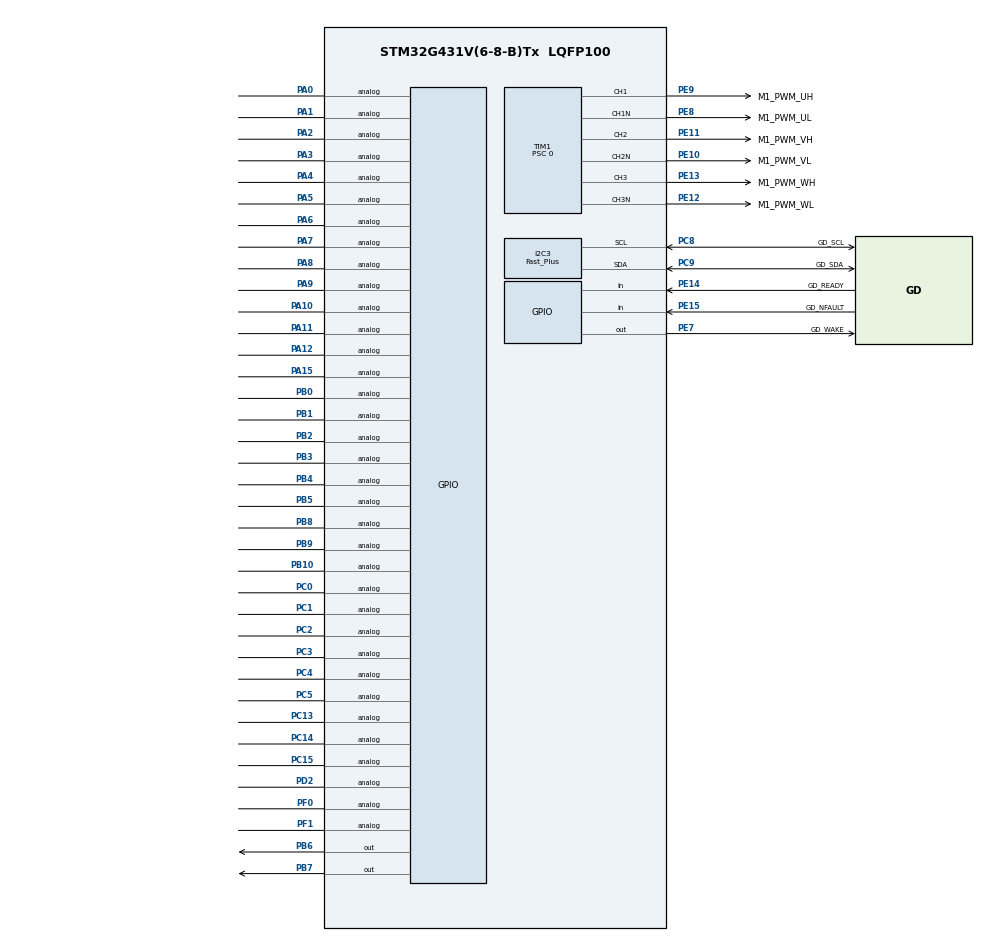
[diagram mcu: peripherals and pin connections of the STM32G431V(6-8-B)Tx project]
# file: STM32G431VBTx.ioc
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Dma.Request0=TIM1_CH4
Dma.TIM1_CH4.0.Direction=DMA_MEMORY_TO_PERIPH
Dma.TIM1_CH4.0.EventEnable=DISABLE
Dma.TIM1_CH4.0.Instance=DMA1_Channel1
Dma.TIM1_CH4.0.MemDataAlignment=DMA_MDATAALIGN_HALFWORD
Dma.TIM1_CH4.0.MemInc=DMA_MINC_ENABLE
Dma.TIM1_CH4.0.Mode=DMA_CIRCULAR
Dma.TIM1_CH4.0.PeriphDataAlignment=DMA_PDATAALIGN_HALFWORD
Dma.TIM1_CH4.0.PeriphInc=DMA_PINC_DISABLE
Dma.TIM1_CH4.0.Polarity=HAL_DMAMUX_REQ_GEN_RISING
Dma.TIM1_CH4.0.Priority=DMA_PRIORITY_HIGH
Dma.TIM1_CH4.0.RequestNumber=1
Dma.TIM1_CH4.0.SignalID=NONE
Dma.TIM1_CH4.0.SyncEnable=DISABLE
Dma.TIM1_CH4.0.SyncPolarity=HAL_DMAMUX_SYNC_NO_EVENT
Dma.TIM1_CH4.0.SyncRequestNumber=1
Dma.TIM1_CH4.0.SyncSignalID=NONE
I2C3.I2C_Speed_Mode=I2C_Fast_Plus
I2C3.Timing=0x4052060F
Mcu.Family=STM32G4
Mcu.Name=STM32G431V(6-8-B)Tx
Mcu.Package=LQFP100
NVIC.DMA1_Channel1_IRQn=true\:0\:0\:false\:false\:true\:false\:true\:true
NVIC.PriorityGroup=NVIC_PRIORITYGROUP_3
NVIC.TIM1_BRK_TIM15_IRQn=true\:6\:0\:true\:true\:true\:1\:true\:true\:true
NVIC.TIM1_CC_IRQn=true\:7\:0\:true\:false\:true\:true\:true\:true
NVIC.TIM1_TRG_COM_TIM17_IRQn=true\:0\:0\:false\:false\:true\:true\:true\:true
NVIC.TIM1_UP_TIM16_IRQn=true\:0\:0\:false\:true\:true\:2\:true\:true\:true
NVIC.TIM7_IRQn=true\:0\:0\:false\:false\:true\:true\:true\:true
PA0.Signal=GPIO_Analog
PA1.Signal=GPIO_Analog
PA10.Signal=GPIO_Analog
PA11.Signal=GPIO_Analog
PA12.Signal=GPIO_Analog
PA13.GPIO_Label=TMS
PA13.Mode=Serial_Wire
PA13.Signal=SYS_JTMS-SWDIO
PA14.GPIO_Label=TCK
PA14.Mode=Serial_Wire
PA14.Signal=SYS_JTCK-SWCLK
PA15.Signal=GPIO_Analog
PA2.Signal=GPIO_Analog
PA3.Signal=GPIO_Analog
PA4.Signal=GPIO_Analog
PA5.Signal=GPIO_Analog
PA6.Signal=GPIO_Analog
PA7.Signal=GPIO_Analog
PA8.Signal=GPIO_Analog
PA9.Signal=GPIO_Analog
PB0.Signal=GPIO_Analog
PB1.Signal=GPIO_Analog
PB10.Signal=GPIO_Analog
PB2.Signal=GPIO_Analog
PB3.Signal=GPIO_Analog
PB4.Signal=GPIO_Analog
PB5.Signal=GPIO_Analog
PB6.Signal=GPIO_Output
PB7.Signal=GPIO_Output
PB8-BOOT0.Signal=GPIO_Analog
PB9.Signal=GPIO_Analog
PC0.Signal=GPIO_Analog
PC1.Signal=GPIO_Analog
PC13.Signal=GPIO_Analog
PC14-OSC32_IN.Signal=GPIO_Analog
PC15-OSC32_OUT.Signal=GPIO_Analog
PC2.Signal=GPIO_Analog
PC3.Signal=GPIO_Analog
PC4.Signal=GPIO_Analog
PC5.Signal=GPIO_Analog
PC8.GPIO_Label=GD_SCL
PC8.GPIO_Pu=GPIO_PULLUP
PC8.Mode=I2C
PC8.Signal=I2C3_SCL
PC9.GPIO_Label=GD_SDA
PC9.GPIO_Pu=GPIO_PULLUP
PC9.Mode=I2C
PC9.Signal=I2C3_SDA
PD2.Signal=GPIO_Analog
PE10.GPIO_Label=M1_PWM_VL
PE10.GPIO_PuPd=GPIO_PULLDOWN
PE10.GPIO_Speed=GPIO_SPEED_FREQ_HIGH
PE10.Mode=PWM Generation2 CH2 CH2N
PE10.Signal=TIM1_CH2N
PE11.GPIO_Label=M1_PWM_VH
PE11.GPIO_PuPd=GPIO_PULLDOWN
PE11.GPIO_Speed=GPIO_SPEED_FREQ_HIGH
PE11.Signal=S_TIM1_CH2
PE12.GPIO_Label=M1_PWM_WL
PE12.GPIO_PuPd=GPIO_PULLDOWN
PE12.GPIO_Speed=GPIO_SPEED_FREQ_HIGH
PE12.Mode=PWM Generation3 CH3 CH3N
PE12.Signal=TIM1_CH3N
PE13.GPIO_Label=M1_PWM_WH
PE13.GPIO_PuPd=GPIO_PULLDOWN
PE13.GPIO_Speed=GPIO_SPEED_FREQ_HIGH
PE13.Signal=S_TIM1_CH3
PE14.GPIO_Label=GD_READY
PE14.GPIO_PuPd=GPIO_PULLUP
PE14.Signal=GPIO_Input
PE15.GPIO_Label=GD_NFAULT
PE15.GPIO_PuPd=GPIO_PULLUP
PE15.Signal=GPIO_Input
PE7.GPIO_Label=GD_WAKE
PE7.Signal=GPIO_Output
PE8.GPIO_Label=M1_PWM_UL
PE8.GPIO_PuPd=GPIO_PULLDOWN
PE8.GPIO_Speed=GPIO_SPEED_FREQ_HIGH
PE8.Mode=PWM Generation1 CH1 CH1N
PE8.Signal=TIM1_CH1N
PE9.GPIO_Label=M1_PWM_UH
PE9.GPIO_PuPd=GPIO_PULLDOWN
PE9.GPIO_Speed=GPIO_SPEED_FREQ_HIGH
PE9.Signal=S_TIM1_CH1
PF0-OSC_IN.Signal=GPIO_Analog
PF1-OSC_OUT.Signal=GPIO_Analog
ProjectManager.HeapSize=0x200
ProjectManager.StackSize=0x400
ProjectManager.TargetToolchain=STM32CubeIDE
RCC.ADC12CLockSelection=RCC_ADC12CLKSOURCE_PLL
RCC.ADC12Freq_Value=170000000
RCC.ADC345CLockSelection=RCC_ADC345CLKSOURCE_PLL
RCC.ADC345Freq_Value=42500000
RCC.AHBFreq_Value=170000000
RCC.APB1Freq_Value=170000000
RCC.APB1TimFreq_Value=170000000
RCC.APB2Freq_Value=170000000
RCC.APB2TimFreq_Value=170000000
RCC.CortexFreq_Value=170000000
RCC.EXTERNAL_CLOCK_VALUE=12288000
RCC.HCLKFreq_Value=170000000
RCC.HSE_VALUE=24000000
RCC.HSI48_VALUE=48000000
RCC.HSI_VALUE=16000000
RCC.LSE_VALUE=32768
RCC.PLLM=RCC_PLLM_DIV4
RCC.PLLN=85
RCC.SYSCLKFreq_VALUE=170000000
RCC.SYSCLKSource=RCC_SYSCLKSOURCE_PLLCLK
RCC.USBFreq_Value=170000000
RCC.VCOOutputFreq_Value=340000000
SH.S_TIM1_CH1.0=TIM1_CH1,PWM Generation1 CH1 CH1N
SH.S_TIM1_CH2.0=TIM1_CH2,PWM Generation2 CH2 CH2N
SH.S_TIM1_CH3.0=TIM1_CH3,PWM Generation3 CH3 CH3N
TIM1.AutoReloadPreload=TIM_AUTORELOAD_PRELOAD_DISABLE
TIM1.AutomaticOutput=TIM_AUTOMATICOUTPUT_DISABLE
TIM1.Break2Filter=3
TIM1.Break2Polarity=TIM_BREAK2POLARITY_HIGH
TIM1.Break2State=TIM_BREAK2_DISABLE
TIM1.BreakFilter=3
TIM1.BreakPolarity=TIM_BREAKPOLARITY_HIGH
TIM1.BreakState=TIM_BREAK_ENABLE
TIM1.Channel-Output\ Compare4\ No\ Output=TIM_CHANNEL_4
TIM1.Channel-PWM\ Generation1\ CH1\ CH1N=TIM_CHANNEL_1
TIM1.Channel-PWM\ Generation2\ CH2\ CH2N=TIM_CHANNEL_2
TIM1.Channel-PWM\ Generation3\ CH3\ CH3N=TIM_CHANNEL_3
TIM1.ClearInputSource=TIM_CLEARINPUTSOURCE_NONE
TIM1.ClockDivision=TIM_CLOCKDIVISION_DIV1
TIM1.CounterMode=TIM_COUNTERMODE_CENTERALIGNED2
TIM1.LockLevel=TIM_LOCKLEVEL_OFF
TIM1.OCIdleState_4=TIM_OCIDLESTATE_RESET
TIM1.OCMode_4=TIM_OCMODE_TOGGLE
TIM1.OCPolarity_4=TIM_OCPOLARITY_HIGH
TIM1.OffStateIDLEMode=TIM_OSSI_ENABLE
TIM1.PeriodNoDither=((PWM_PERIOD_CYCLES) / 2)
TIM1.Prescaler=0
TIM1.RepetitionCounter=0
TIM1.SourceBRK2COMP1=TIM_BREAKINPUTSOURCE_DISABLE
TIM1.SourceBRK2COMP2=TIM_BREAKINPUTSOURCE_DISABLE
TIM1.SourceBRK2COMP4=TIM_BREAKINPUTSOURCE_DISABLE
TIM1.SourceBRK2DigInput=TIM_BREAKINPUTSOURCE_DISABLE
TIM1.SourceBRKCOMP3=TIM_BREAKINPUTSOURCE_DISABLE
TIM1.TIM_MasterOutputTrigger=TIM_TRGO_OC4REF
TIM1.TIM_MasterOutputTrigger2=TIM_TRGO2_RESET
TIM1.TIM_MasterSlaveMode=TIM_MASTERSLAVEMODE_DISABLE
TIM7.PeriodNoDither=42499
VP_CORDIC_VS_CORDIC.Mode=CORDIC_Activate
VP_SYS_VS_DBSignals.Mode=DisableDeadBatterySignals
VP_TIM1_VS_no_output4.Mode=Output Compare4 No Output
VP_TIM7_VS_ClockSourceINT.Mode=Enable_Timer
board=custom

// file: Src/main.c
/* USER CODE BEGIN Header */
/**
  ******************************************************************************
  * @file           : main.c
  * @brief          : Main program body
  ******************************************************************************
  * @attention
  *
  * Copyright (c) 2025 STMicroelectronics.
  * All rights reserved.
  *
  * This software is licensed under terms that can be found in the LICENSE file
  * in the root directory of this software component.
  * If no LICENSE file comes with this software, it is provided AS-IS.
  *
  ******************************************************************************
  */
/* USER CODE END Header */
#include "main.h"

/* USER CODE BEGIN Includes */
#include "SocketBoardTest.h"

/* USER CODE END Includes */

void SystemClock_Config(void);
static void MX_GPIO_Init(void);
static void MX_DMA_Init(void);
static void MX_CORDIC_Init(void);
static void MX_TIM1_Init(void);
static void MX_I2C3_Init(void);
static void MX_TIM7_Init(void);
static void MX_NVIC_Init(void);

/* USER CODE BEGIN 0 */
uint8_t testProcess = 0;
uint8_t cGPIOTestResults[GPIO_TEST_PIN_CNT]; // 테스트 결과 저장 배열 (0: 실패, 1: 성공)

/* USER CODE END 0 */

int main(void)
{

  /* MCU Configuration--------------------------------------------------------*/

  /* Reset of all peripherals, Initializes the Flash interface and the Systick. */
  LL_APB2_GRP1_EnableClock(LL_APB2_GRP1_PERIPH_SYSCFG);
  LL_APB1_GRP1_EnableClock(LL_APB1_GRP1_PERIPH_PWR);

  /* System interrupt init*/
  NVIC_SetPriorityGrouping(NVIC_PRIORITYGROUP_3);

  /** Disable the internal Pull-Up in Dead Battery pins of UCPD peripheral
  */
  LL_PWR_DisableUCPDDeadBattery();

  /* Configure the system clock */
  SystemClock_Config();

  /* Initialize all configured peripherals */
  MX_GPIO_Init();
  MX_DMA_Init();
  MX_CORDIC_Init();
  MX_TIM1_Init();
  MX_I2C3_Init();
  MX_TIM7_Init();

  /* Initialize interrupts */
  MX_NVIC_Init();

  /* Infinite loop */
  /* USER CODE BEGIN WHILE */

  while (1)
  {
	  if(testProcess == 1)
	  {
		  memset(cGPIOTestResults, 0, sizeof(cGPIOTestResults));
		  GPIO_TestProcess(cGPIOTestResults);
		  testProcess = 0;
	  }

    /* USER CODE END WHILE */

  }
}

void SystemClock_Config(void)
{
  LL_FLASH_SetLatency(LL_FLASH_LATENCY_4);
  while(LL_FLASH_GetLatency() != LL_FLASH_LATENCY_4)
  {
  }
  LL_PWR_EnableRange1BoostMode();
  LL_RCC_HSI_Enable();
   /* Wait till HSI is ready */
  while(LL_RCC_HSI_IsReady() != 1)
  {
  }

  LL_RCC_HSI_SetCalibTrimming(64);
  LL_RCC_PLL_ConfigDomain_SYS(LL_RCC_PLLSOURCE_HSI, LL_RCC_PLLM_DIV_4, 85, LL_RCC_PLLR_DIV_2);
  LL_RCC_PLL_EnableDomain_SYS();
  LL_RCC_PLL_Enable();
   /* Wait till PLL is ready */
  while(LL_RCC_PLL_IsReady() != 1)
  {
  }

  LL_RCC_SetSysClkSource(LL_RCC_SYS_CLKSOURCE_PLL);
  LL_RCC_SetAHBPrescaler(LL_RCC_SYSCLK_DIV_2);
   /* Wait till System clock is ready */
  while(LL_RCC_GetSysClkSource() != LL_RCC_SYS_CLKSOURCE_STATUS_PLL)
  {
  }

  /* Insure 1us transition state at intermediate medium speed clock*/
  for (__IO uint32_t i = (170 >> 1); i !=0; i--);

  /* Set AHB prescaler*/
  LL_RCC_SetAHBPrescaler(LL_RCC_SYSCLK_DIV_1);
  LL_RCC_SetAPB1Prescaler(LL_RCC_APB1_DIV_1);
  LL_RCC_SetAPB2Prescaler(LL_RCC_APB2_DIV_1);

  LL_Init1msTick(170000000);

  LL_SetSystemCoreClock(170000000);
}

/**
  * @brief NVIC Configuration.
  * @retval None
  */
static void MX_NVIC_Init(void)
{
  /* TIM1_BRK_TIM15_IRQn interrupt configuration */
  NVIC_SetPriority(TIM1_BRK_TIM15_IRQn, NVIC_EncodePriority(NVIC_GetPriorityGrouping(),6, 0));
  NVIC_EnableIRQ(TIM1_BRK_TIM15_IRQn);
  /* TIM1_UP_TIM16_IRQn interrupt configuration */
  NVIC_SetPriority(TIM1_UP_TIM16_IRQn, NVIC_EncodePriority(NVIC_GetPriorityGrouping(),0, 0));
  NVIC_EnableIRQ(TIM1_UP_TIM16_IRQn);
}

static void MX_CORDIC_Init(void)
{

  /* Peripheral clock enable */
  LL_AHB1_GRP1_EnableClock(LL_AHB1_GRP1_PERIPH_CORDIC);

  /* nothing else to be configured */

}

static void MX_I2C3_Init(void)
{

  LL_I2C_InitTypeDef I2C_InitStruct = {0};

  LL_GPIO_InitTypeDef GPIO_InitStruct = {0};

  LL_RCC_SetI2CClockSource(LL_RCC_I2C3_CLKSOURCE_PCLK1);

  LL_AHB2_GRP1_EnableClock(LL_AHB2_GRP1_PERIPH_GPIOC);
  /**I2C3 GPIO Configuration
  PC8   ------> I2C3_SCL
  PC9   ------> I2C3_SDA
  */
  GPIO_InitStruct.Pin = GD_SCL_Pin;
  GPIO_InitStruct.Mode = LL_GPIO_MODE_ALTERNATE;
  GPIO_InitStruct.Speed = LL_GPIO_SPEED_FREQ_LOW;
  GPIO_InitStruct.OutputType = LL_GPIO_OUTPUT_OPENDRAIN;
  GPIO_InitStruct.Pull = LL_GPIO_PULL_UP;
  GPIO_InitStruct.Alternate = LL_GPIO_AF_8;
  LL_GPIO_Init(GD_SCL_GPIO_Port, &GPIO_InitStruct);

  GPIO_InitStruct.Pin = GD_SDA_Pin;
  GPIO_InitStruct.Mode = LL_GPIO_MODE_ALTERNATE;
  GPIO_InitStruct.Speed = LL_GPIO_SPEED_FREQ_LOW;
  GPIO_InitStruct.OutputType = LL_GPIO_OUTPUT_OPENDRAIN;
  GPIO_InitStruct.Pull = LL_GPIO_PULL_UP;
  GPIO_InitStruct.Alternate = LL_GPIO_AF_8;
  LL_GPIO_Init(GD_SDA_GPIO_Port, &GPIO_InitStruct);

  /* Peripheral clock enable */
  LL_APB1_GRP1_EnableClock(LL_APB1_GRP1_PERIPH_I2C3);

  /** I2C Initialization
  */
  I2C_InitStruct.PeripheralMode = LL_I2C_MODE_I2C;
  I2C_InitStruct.Timing = 0x4052060F;
  I2C_InitStruct.AnalogFilter = LL_I2C_ANALOGFILTER_ENABLE;
  I2C_InitStruct.DigitalFilter = 0;
  I2C_InitStruct.OwnAddress1 = 0;
  I2C_InitStruct.TypeAcknowledge = LL_I2C_ACK;
  I2C_InitStruct.OwnAddrSize = LL_I2C_OWNADDRESS1_7BIT;
  LL_I2C_Init(I2C3, &I2C_InitStruct);
  LL_I2C_EnableAutoEndMode(I2C3);
  LL_I2C_SetOwnAddress2(I2C3, 0, LL_I2C_OWNADDRESS2_NOMASK);
  LL_I2C_DisableOwnAddress2(I2C3);
  LL_I2C_DisableGeneralCall(I2C3);
  LL_I2C_EnableClockStretching(I2C3);

  /** I2C Fast mode Plus enable
  */
  LL_SYSCFG_EnableFastModePlus(LL_SYSCFG_I2C_FASTMODEPLUS_I2C3);

}

static void MX_TIM1_Init(void)
{

  LL_TIM_InitTypeDef TIM_InitStruct = {0};
  LL_TIM_OC_InitTypeDef TIM_OC_InitStruct = {0};
  LL_TIM_BDTR_InitTypeDef TIM_BDTRInitStruct = {0};

  LL_GPIO_InitTypeDef GPIO_InitStruct = {0};

  /* Peripheral clock enable */
  LL_APB2_GRP1_EnableClock(LL_APB2_GRP1_PERIPH_TIM1);

  /* TIM1 DMA Init */

  /* TIM1_CH4 Init */
  LL_DMA_SetPeriphRequest(DMA1, LL_DMA_CHANNEL_1, LL_DMAMUX_REQ_TIM1_CH4);

  LL_DMA_SetDataTransferDirection(DMA1, LL_DMA_CHANNEL_1, LL_DMA_DIRECTION_MEMORY_TO_PERIPH);

  LL_DMA_SetChannelPriorityLevel(DMA1, LL_DMA_CHANNEL_1, LL_DMA_PRIORITY_HIGH);

  LL_DMA_SetMode(DMA1, LL_DMA_CHANNEL_1, LL_DMA_MODE_CIRCULAR);

  LL_DMA_SetPeriphIncMode(DMA1, LL_DMA_CHANNEL_1, LL_DMA_PERIPH_NOINCREMENT);

  LL_DMA_SetMemoryIncMode(DMA1, LL_DMA_CHANNEL_1, LL_DMA_MEMORY_INCREMENT);

  LL_DMA_SetPeriphSize(DMA1, LL_DMA_CHANNEL_1, LL_DMA_PDATAALIGN_HALFWORD);

  LL_DMA_SetMemorySize(DMA1, LL_DMA_CHANNEL_1, LL_DMA_MDATAALIGN_HALFWORD);

  /* TIM1 interrupt Init */
  NVIC_SetPriority(TIM1_TRG_COM_TIM17_IRQn, NVIC_EncodePriority(NVIC_GetPriorityGrouping(),0, 0));
  NVIC_EnableIRQ(TIM1_TRG_COM_TIM17_IRQn);
  NVIC_SetPriority(TIM1_CC_IRQn, NVIC_EncodePriority(NVIC_GetPriorityGrouping(),7, 0));
  NVIC_EnableIRQ(TIM1_CC_IRQn);

  TIM_InitStruct.Prescaler = 0;
  TIM_InitStruct.CounterMode = LL_TIM_COUNTERMODE_CENTER_UP;
  TIM_InitStruct.Autoreload = ((PWM_PERIOD_CYCLES) / 2);
  TIM_InitStruct.ClockDivision = LL_TIM_CLOCKDIVISION_DIV1;
  TIM_InitStruct.RepetitionCounter = 0;
  LL_TIM_Init(TIM1, &TIM_InitStruct);
  LL_TIM_DisableARRPreload(TIM1);
  LL_TIM_OC_EnablePreload(TIM1, LL_TIM_CHANNEL_CH1);
  TIM_OC_InitStruct.OCMode = LL_TIM_OCMODE_PWM1;
  TIM_OC_InitStruct.OCState = LL_TIM_OCSTATE_DISABLE;
  TIM_OC_InitStruct.OCNState = LL_TIM_OCSTATE_DISABLE;
  TIM_OC_InitStruct.CompareValue = 0;
  TIM_OC_InitStruct.OCPolarity = LL_TIM_OCPOLARITY_HIGH;
  TIM_OC_InitStruct.OCNPolarity = LL_TIM_OCPOLARITY_HIGH;
  TIM_OC_InitStruct.OCIdleState = LL_TIM_OCIDLESTATE_LOW;
  TIM_OC_InitStruct.OCNIdleState = LL_TIM_OCIDLESTATE_LOW;
  LL_TIM_OC_Init(TIM1, LL_TIM_CHANNEL_CH1, &TIM_OC_InitStruct);
  LL_TIM_OC_DisableFast(TIM1, LL_TIM_CHANNEL_CH1);
  LL_TIM_OC_EnablePreload(TIM1, LL_TIM_CHANNEL_CH2);
  LL_TIM_OC_Init(TIM1, LL_TIM_CHANNEL_CH2, &TIM_OC_InitStruct);
  LL_TIM_OC_DisableFast(TIM1, LL_TIM_CHANNEL_CH2);
  LL_TIM_OC_EnablePreload(TIM1, LL_TIM_CHANNEL_CH3);
  LL_TIM_OC_Init(TIM1, LL_TIM_CHANNEL_CH3, &TIM_OC_InitStruct);
  LL_TIM_OC_DisableFast(TIM1, LL_TIM_CHANNEL_CH3);
  TIM_OC_InitStruct.OCMode = LL_TIM_OCMODE_TOGGLE;
  LL_TIM_OC_Init(TIM1, LL_TIM_CHANNEL_CH4, &TIM_OC_InitStruct);
  LL_TIM_OC_DisableFast(TIM1, LL_TIM_CHANNEL_CH4);
  LL_TIM_SetTriggerOutput(TIM1, LL_TIM_TRGO_OC4REF);
  LL_TIM_SetTriggerOutput2(TIM1, LL_TIM_TRGO2_RESET);
  LL_TIM_DisableMasterSlaveMode(TIM1);
  TIM_BDTRInitStruct.OSSRState = LL_TIM_OSSR_DISABLE;
  TIM_BDTRInitStruct.OSSIState = LL_TIM_OSSI_ENABLE;
  TIM_BDTRInitStruct.LockLevel = LL_TIM_LOCKLEVEL_OFF;
  TIM_BDTRInitStruct.DeadTime = 0;
  TIM_BDTRInitStruct.BreakState = LL_TIM_BREAK_ENABLE;
  TIM_BDTRInitStruct.BreakPolarity = LL_TIM_BREAK_POLARITY_HIGH;
  TIM_BDTRInitStruct.BreakFilter = LL_TIM_BREAK_FILTER_FDIV1_N8;
  TIM_BDTRInitStruct.BreakAFMode = LL_TIM_BREAK_AFMODE_INPUT;
  TIM_BDTRInitStruct.Break2State = LL_TIM_BREAK2_DISABLE;
  TIM_BDTRInitStruct.Break2Polarity = LL_TIM_BREAK2_POLARITY_HIGH;
  TIM_BDTRInitStruct.Break2Filter = LL_TIM_BREAK2_FILTER_FDIV1_N8;
  TIM_BDTRInitStruct.Break2AFMode = LL_TIM_BREAK_AFMODE_INPUT;
  TIM_BDTRInitStruct.AutomaticOutput = LL_TIM_AUTOMATICOUTPUT_DISABLE;
  LL_TIM_BDTR_Init(TIM1, &TIM_BDTRInitStruct);
  LL_AHB2_GRP1_EnableClock(LL_AHB2_GRP1_PERIPH_GPIOE);
  /**TIM1 GPIO Configuration
  PE8   ------> TIM1_CH1N
  PE9   ------> TIM1_CH1
  PE10   ------> TIM1_CH2N
  PE11   ------> TIM1_CH2
  PE12   ------> TIM1_CH3N
  PE13   ------> TIM1_CH3
  */
  GPIO_InitStruct.Pin = M1_PWM_UL_Pin;
  GPIO_InitStruct.Mode = LL_GPIO_MODE_ALTERNATE;
  GPIO_InitStruct.Speed = LL_GPIO_SPEED_FREQ_HIGH;
  GPIO_InitStruct.OutputType = LL_GPIO_OUTPUT_PUSHPULL;
  GPIO_InitStruct.Pull = LL_GPIO_PULL_DOWN;
  GPIO_InitStruct.Alternate = LL_GPIO_AF_2;
  LL_GPIO_Init(M1_PWM_UL_GPIO_Port, &GPIO_InitStruct);

  GPIO_InitStruct.Pin = M1_PWM_UH_Pin;
  GPIO_InitStruct.Mode = LL_GPIO_MODE_ALTERNATE;
  GPIO_InitStruct.Speed = LL_GPIO_SPEED_FREQ_HIGH;
  GPIO_InitStruct.OutputType = LL_GPIO_OUTPUT_PUSHPULL;
  GPIO_InitStruct.Pull = LL_GPIO_PULL_DOWN;
  GPIO_InitStruct.Alternate = LL_GPIO_AF_2;
  LL_GPIO_Init(M1_PWM_UH_GPIO_Port, &GPIO_InitStruct);

  GPIO_InitStruct.Pin = M1_PWM_VL_Pin;
  GPIO_InitStruct.Mode = LL_GPIO_MODE_ALTERNATE;
  GPIO_InitStruct.Speed = LL_GPIO_SPEED_FREQ_HIGH;
  GPIO_InitStruct.OutputType = LL_GPIO_OUTPUT_PUSHPULL;
  GPIO_InitStruct.Pull = LL_GPIO_PULL_DOWN;
  GPIO_InitStruct.Alternate = LL_GPIO_AF_2;
  LL_GPIO_Init(M1_PWM_VL_GPIO_Port, &GPIO_InitStruct);

  GPIO_InitStruct.Pin = M1_PWM_VH_Pin;
  GPIO_InitStruct.Mode = LL_GPIO_MODE_ALTERNATE;
  GPIO_InitStruct.Speed = LL_GPIO_SPEED_FREQ_HIGH;
  GPIO_InitStruct.OutputType = LL_GPIO_OUTPUT_PUSHPULL;
  GPIO_InitStruct.Pull = LL_GPIO_PULL_DOWN;
  GPIO_InitStruct.Alternate = LL_GPIO_AF_2;
  LL_GPIO_Init(M1_PWM_VH_GPIO_Port, &GPIO_InitStruct);

  GPIO_InitStruct.Pin = M1_PWM_WL_Pin;
  GPIO_InitStruct.Mode = LL_GPIO_MODE_ALTERNATE;
  GPIO_InitStruct.Speed = LL_GPIO_SPEED_FREQ_HIGH;
  GPIO_InitStruct.OutputType = LL_GPIO_OUTPUT_PUSHPULL;
  GPIO_InitStruct.Pull = LL_GPIO_PULL_DOWN;
  GPIO_InitStruct.Alternate = LL_GPIO_AF_2;
  LL_GPIO_Init(M1_PWM_WL_GPIO_Port, &GPIO_InitStruct);

  GPIO_InitStruct.Pin = M1_PWM_WH_Pin;
  GPIO_InitStruct.Mode = LL_GPIO_MODE_ALTERNATE;
  GPIO_InitStruct.Speed = LL_GPIO_SPEED_FREQ_HIGH;
  GPIO_InitStruct.OutputType = LL_GPIO_OUTPUT_PUSHPULL;
  GPIO_InitStruct.Pull = LL_GPIO_PULL_DOWN;
  GPIO_InitStruct.Alternate = LL_GPIO_AF_2;
  LL_GPIO_Init(M1_PWM_WH_GPIO_Port, &GPIO_InitStruct);

}

static void MX_TIM7_Init(void)
{

  LL_TIM_InitTypeDef TIM_InitStruct = {0};

  /* Peripheral clock enable */
  LL_APB1_GRP1_EnableClock(LL_APB1_GRP1_PERIPH_TIM7);

  /* TIM7 interrupt Init */
  NVIC_SetPriority(TIM7_IRQn, NVIC_EncodePriority(NVIC_GetPriorityGrouping(),0, 0));
  NVIC_EnableIRQ(TIM7_IRQn);

  TIM_InitStruct.Prescaler = 0;
  TIM_InitStruct.CounterMode = LL_TIM_COUNTERMODE_UP;
  TIM_InitStruct.Autoreload = 42499;
  LL_TIM_Init(TIM7, &TIM_InitStruct);
  LL_TIM_DisableARRPreload(TIM7);
  LL_TIM_SetTriggerOutput(TIM7, LL_TIM_TRGO_RESET);
  LL_TIM_DisableMasterSlaveMode(TIM7);

}

static void MX_DMA_Init(void)
{

  /* Init with LL driver */
  /* DMA controller clock enable */
  LL_AHB1_GRP1_EnableClock(LL_AHB1_GRP1_PERIPH_DMAMUX1);
  LL_AHB1_GRP1_EnableClock(LL_AHB1_GRP1_PERIPH_DMA1);

  /* DMA interrupt init */
  /* DMA1_Channel1_IRQn interrupt configuration */
  NVIC_SetPriority(DMA1_Channel1_IRQn, NVIC_EncodePriority(NVIC_GetPriorityGrouping(),0, 0));
  NVIC_EnableIRQ(DMA1_Channel1_IRQn);

}

static void MX_GPIO_Init(void)
{
  LL_GPIO_InitTypeDef GPIO_InitStruct = {0};

  /* GPIO Ports Clock Enable */
  LL_AHB2_GRP1_EnableClock(LL_AHB2_GRP1_PERIPH_GPIOE);
  LL_AHB2_GRP1_EnableClock(LL_AHB2_GRP1_PERIPH_GPIOC);
  LL_AHB2_GRP1_EnableClock(LL_AHB2_GRP1_PERIPH_GPIOF);
  LL_AHB2_GRP1_EnableClock(LL_AHB2_GRP1_PERIPH_GPIOG);
  LL_AHB2_GRP1_EnableClock(LL_AHB2_GRP1_PERIPH_GPIOA);
  LL_AHB2_GRP1_EnableClock(LL_AHB2_GRP1_PERIPH_GPIOB);
  LL_AHB2_GRP1_EnableClock(LL_AHB2_GRP1_PERIPH_GPIOD);

  /**/
  LL_GPIO_ResetOutputPin(GD_WAKE_GPIO_Port, GD_WAKE_Pin);

  /**/
  LL_GPIO_ResetOutputPin(GPIOB, LL_GPIO_PIN_6);

  /**/
  LL_GPIO_ResetOutputPin(GPIOB, LL_GPIO_PIN_7);

  /**/
  GPIO_InitStruct.Pin = LL_GPIO_PIN_2;
  GPIO_InitStruct.Mode = LL_GPIO_MODE_ANALOG;
  GPIO_InitStruct.Pull = LL_GPIO_PULL_NO;
  LL_GPIO_Init(GPIOE, &GPIO_InitStruct);

  /**/
  GPIO_InitStruct.Pin = LL_GPIO_PIN_3;
  GPIO_InitStruct.Mode = LL_GPIO_MODE_ANALOG;
  GPIO_InitStruct.Pull = LL_GPIO_PULL_NO;
  LL_GPIO_Init(GPIOE, &GPIO_InitStruct);

  /**/
  GPIO_InitStruct.Pin = LL_GPIO_PIN_4;
  GPIO_InitStruct.Mode = LL_GPIO_MODE_ANALOG;
  GPIO_InitStruct.Pull = LL_GPIO_PULL_NO;
  LL_GPIO_Init(GPIOE, &GPIO_InitStruct);

  /**/
  GPIO_InitStruct.Pin = LL_GPIO_PIN_5;
  GPIO_InitStruct.Mode = LL_GPIO_MODE_ANALOG;
  GPIO_InitStruct.Pull = LL_GPIO_PULL_NO;
  LL_GPIO_Init(GPIOE, &GPIO_InitStruct);

  /**/
  GPIO_InitStruct.Pin = LL_GPIO_PIN_6;
  GPIO_InitStruct.Mode = LL_GPIO_MODE_ANALOG;
  GPIO_InitStruct.Pull = LL_GPIO_PULL_NO;
  LL_GPIO_Init(GPIOE, &GPIO_InitStruct);

  /**/
  GPIO_InitStruct.Pin = LL_GPIO_PIN_13;
  GPIO_InitStruct.Mode = LL_GPIO_MODE_ANALOG;
  GPIO_InitStruct.Pull = LL_GPIO_PULL_NO;
  LL_GPIO_Init(GPIOC, &GPIO_InitStruct);

  /**/
  GPIO_InitStruct.Pin = LL_GPIO_PIN_14;
  GPIO_InitStruct.Mode = LL_GPIO_MODE_ANALOG;
  GPIO_InitStruct.Pull = LL_GPIO_PULL_NO;
  LL_GPIO_Init(GPIOC, &GPIO_InitStruct);

  /**/
  GPIO_InitStruct.Pin = LL_GPIO_PIN_15;
  GPIO_InitStruct.Mode = LL_GPIO_MODE_ANALOG;
  GPIO_InitStruct.Pull = LL_GPIO_PULL_NO;
  LL_GPIO_Init(GPIOC, &GPIO_InitStruct);

  /**/
  GPIO_InitStruct.Pin = LL_GPIO_PIN_9;
  GPIO_InitStruct.Mode = LL_GPIO_MODE_ANALOG;
  GPIO_InitStruct.Pull = LL_GPIO_PULL_NO;
  LL_GPIO_Init(GPIOF, &GPIO_InitStruct);

  /**/
  GPIO_InitStruct.Pin = LL_GPIO_PIN_10;
  GPIO_InitStruct.Mode = LL_GPIO_MODE_ANALOG;
  GPIO_InitStruct.Pull = LL_GPIO_PULL_NO;
  LL_GPIO_Init(GPIOF, &GPIO_InitStruct);

  /**/
  GPIO_InitStruct.Pin = LL_GPIO_PIN_0;
  GPIO_InitStruct.Mode = LL_GPIO_MODE_ANALOG;
  GPIO_InitStruct.Pull = LL_GPIO_PULL_NO;
  LL_GPIO_Init(GPIOF, &GPIO_InitStruct);

  /**/
  GPIO_InitStruct.Pin = LL_GPIO_PIN_1;
  GPIO_InitStruct.Mode = LL_GPIO_MODE_ANALOG;
  GPIO_InitStruct.Pull = LL_GPIO_PULL_NO;
  LL_GPIO_Init(GPIOF, &GPIO_InitStruct);

  /**/
  GPIO_InitStruct.Pin = LL_GPIO_PIN_10;
  GPIO_InitStruct.Mode = LL_GPIO_MODE_ANALOG;
  GPIO_InitStruct.Pull = LL_GPIO_PULL_NO;
  LL_GPIO_Init(GPIOG, &GPIO_InitStruct);

  /**/
  GPIO_InitStruct.Pin = LL_GPIO_PIN_0;
  GPIO_InitStruct.Mode = LL_GPIO_MODE_ANALOG;
  GPIO_InitStruct.Pull = LL_GPIO_PULL_NO;
  LL_GPIO_Init(GPIOC, &GPIO_InitStruct);

  /**/
  GPIO_InitStruct.Pin = LL_GPIO_PIN_1;
  GPIO_InitStruct.Mode = LL_GPIO_MODE_ANALOG;
  GPIO_InitStruct.Pull = LL_GPIO_PULL_NO;
  LL_GPIO_Init(GPIOC, &GPIO_InitStruct);

  /**/
  GPIO_InitStruct.Pin = LL_GPIO_PIN_2;
  GPIO_InitStruct.Mode = LL_GPIO_MODE_ANALOG;
  GPIO_InitStruct.Pull = LL_GPIO_PULL_NO;
  LL_GPIO_Init(GPIOC, &GPIO_InitStruct);

  /**/
  GPIO_InitStruct.Pin = LL_GPIO_PIN_3;
  GPIO_InitStruct.Mode = LL_GPIO_MODE_ANALOG;
  GPIO_InitStruct.Pull = LL_GPIO_PULL_NO;
  LL_GPIO_Init(GPIOC, &GPIO_InitStruct);

  /**/
  GPIO_InitStruct.Pin = LL_GPIO_PIN_2;
  GPIO_InitStruct.Mode = LL_GPIO_MODE_ANALOG;
  GPIO_InitStruct.Pull = LL_GPIO_PULL_NO;
  LL_GPIO_Init(GPIOF, &GPIO_InitStruct);

  /**/
  GPIO_InitStruct.Pin = LL_GPIO_PIN_0;
  GPIO_InitStruct.Mode = LL_GPIO_MODE_ANALOG;
  GPIO_InitStruct.Pull = LL_GPIO_PULL_NO;
  LL_GPIO_Init(GPIOA, &GPIO_InitStruct);

  /**/
  GPIO_InitStruct.Pin = LL_GPIO_PIN_1;
  GPIO_InitStruct.Mode = LL_GPIO_MODE_ANALOG;
  GPIO_InitStruct.Pull = LL_GPIO_PULL_NO;
  LL_GPIO_Init(GPIOA, &GPIO_InitStruct);

  /**/
  GPIO_InitStruct.Pin = LL_GPIO_PIN_2;
  GPIO_InitStruct.Mode = LL_GPIO_MODE_ANALOG;
  GPIO_InitStruct.Pull = LL_GPIO_PULL_NO;
  LL_GPIO_Init(GPIOA, &GPIO_InitStruct);

  /**/
  GPIO_InitStruct.Pin = LL_GPIO_PIN_3;
  GPIO_InitStruct.Mode = LL_GPIO_MODE_ANALOG;
  GPIO_InitStruct.Pull = LL_GPIO_PULL_NO;
  LL_GPIO_Init(GPIOA, &GPIO_InitStruct);

  /**/
  GPIO_InitStruct.Pin = LL_GPIO_PIN_4;
  GPIO_InitStruct.Mode = LL_GPIO_MODE_ANALOG;
  GPIO_InitStruct.Pull = LL_GPIO_PULL_NO;
  LL_GPIO_Init(GPIOA, &GPIO_InitStruct);

  /**/
  GPIO_InitStruct.Pin = LL_GPIO_PIN_5;
  GPIO_InitStruct.Mode = LL_GPIO_MODE_ANALOG;
  GPIO_InitStruct.Pull = LL_GPIO_PULL_NO;
  LL_GPIO_Init(GPIOA, &GPIO_InitStruct);

  /**/
  GPIO_InitStruct.Pin = LL_GPIO_PIN_6;
  GPIO_InitStruct.Mode = LL_GPIO_MODE_ANALOG;
  GPIO_InitStruct.Pull = LL_GPIO_PULL_NO;
  LL_GPIO_Init(GPIOA, &GPIO_InitStruct);

  /**/
  GPIO_InitStruct.Pin = LL_GPIO_PIN_7;
  GPIO_InitStruct.Mode = LL_GPIO_MODE_ANALOG;
  GPIO_InitStruct.Pull = LL_GPIO_PULL_NO;
  LL_GPIO_Init(GPIOA, &GPIO_InitStruct);

  /**/
  GPIO_InitStruct.Pin = LL_GPIO_PIN_4;
  GPIO_InitStruct.Mode = LL_GPIO_MODE_ANALOG;
  GPIO_InitStruct.Pull = LL_GPIO_PULL_NO;
  LL_GPIO_Init(GPIOC, &GPIO_InitStruct);

  /**/
  GPIO_InitStruct.Pin = LL_GPIO_PIN_5;
  GPIO_InitStruct.Mode = LL_GPIO_MODE_ANALOG;
  GPIO_InitStruct.Pull = LL_GPIO_PULL_NO;
  LL_GPIO_Init(GPIOC, &GPIO_InitStruct);

  /**/
  GPIO_InitStruct.Pin = LL_GPIO_PIN_0;
  GPIO_InitStruct.Mode = LL_GPIO_MODE_ANALOG;
  GPIO_InitStruct.Pull = LL_GPIO_PULL_NO;
  LL_GPIO_Init(GPIOB, &GPIO_InitStruct);

  /**/
  GPIO_InitStruct.Pin = LL_GPIO_PIN_1;
  GPIO_InitStruct.Mode = LL_GPIO_MODE_ANALOG;
  GPIO_InitStruct.Pull = LL_GPIO_PULL_NO;
  LL_GPIO_Init(GPIOB, &GPIO_InitStruct);

  /**/
  GPIO_InitStruct.Pin = LL_GPIO_PIN_2;
  GPIO_InitStruct.Mode = LL_GPIO_MODE_ANALOG;
  GPIO_InitStruct.Pull = LL_GPIO_PULL_NO;
  LL_GPIO_Init(GPIOB, &GPIO_InitStruct);

  /**/
  GPIO_InitStruct.Pin = GD_WAKE_Pin;
  GPIO_InitStruct.Mode = LL_GPIO_MODE_OUTPUT;
  GPIO_InitStruct.Speed = LL_GPIO_SPEED_FREQ_LOW;
  GPIO_InitStruct.OutputType = LL_GPIO_OUTPUT_PUSHPULL;
  GPIO_InitStruct.Pull = LL_GPIO_PULL_NO;
  LL_GPIO_Init(GD_WAKE_GPIO_Port, &GPIO_InitStruct);

  /**/
  GPIO_InitStruct.Pin = GD_READY_Pin;
  GPIO_InitStruct.Mode = LL_GPIO_MODE_INPUT;
  GPIO_InitStruct.Pull = LL_GPIO_PULL_UP;
  LL_GPIO_Init(GD_READY_GPIO_Port, &GPIO_InitStruct);

  /**/
  GPIO_InitStruct.Pin = GD_NFAULT_Pin;
  GPIO_InitStruct.Mode = LL_GPIO_MODE_INPUT;
  GPIO_InitStruct.Pull = LL_GPIO_PULL_UP;
  LL_GPIO_Init(GD_NFAULT_GPIO_Port, &GPIO_InitStruct);

  /**/
  GPIO_InitStruct.Pin = LL_GPIO_PIN_10;
  GPIO_InitStruct.Mode = LL_GPIO_MODE_ANALOG;
  GPIO_InitStruct.Pull = LL_GPIO_PULL_NO;
  LL_GPIO_Init(GPIOB, &GPIO_InitStruct);

  /**/
  GPIO_InitStruct.Pin = LL_GPIO_PIN_11;
  GPIO_InitStruct.Mode = LL_GPIO_MODE_ANALOG;
  GPIO_InitStruct.Pull = LL_GPIO_PULL_NO;
  LL_GPIO_Init(GPIOB, &GPIO_InitStruct);

  /**/
  GPIO_InitStruct.Pin = LL_GPIO_PIN_12;
  GPIO_InitStruct.Mode = LL_GPIO_MODE_ANALOG;
  GPIO_InitStruct.Pull = LL_GPIO_PULL_NO;
  LL_GPIO_Init(GPIOB, &GPIO_InitStruct);

  /**/
  GPIO_InitStruct.Pin = LL_GPIO_PIN_13;
  GPIO_InitStruct.Mode = LL_GPIO_MODE_ANALOG;
  GPIO_InitStruct.Pull = LL_GPIO_PULL_NO;
  LL_GPIO_Init(GPIOB, &GPIO_InitStruct);

  /**/
  GPIO_InitStruct.Pin = LL_GPIO_PIN_14;
  GPIO_InitStruct.Mode = LL_GPIO_MODE_ANALOG;
  GPIO_InitStruct.Pull = LL_GPIO_PULL_NO;
  LL_GPIO_Init(GPIOB, &GPIO_InitStruct);

  /**/
  GPIO_InitStruct.Pin = LL_GPIO_PIN_15;
  GPIO_InitStruct.Mode = LL_GPIO_MODE_ANALOG;
  GPIO_InitStruct.Pull = LL_GPIO_PULL_NO;
  LL_GPIO_Init(GPIOB, &GPIO_InitStruct);

  /**/
  GPIO_InitStruct.Pin = LL_GPIO_PIN_8;
  GPIO_InitStruct.Mode = LL_GPIO_MODE_ANALOG;
  GPIO_InitStruct.Pull = LL_GPIO_PULL_NO;
  LL_GPIO_Init(GPIOD, &GPIO_InitStruct);

  /**/
  GPIO_InitStruct.Pin = LL_GPIO_PIN_9;
  GPIO_InitStruct.Mode = LL_GPIO_MODE_ANALOG;
  GPIO_InitStruct.Pull = LL_GPIO_PULL_NO;
  LL_GPIO_Init(GPIOD, &GPIO_InitStruct);

  /**/
  GPIO_InitStruct.Pin = LL_GPIO_PIN_10;
  GPIO_InitStruct.Mode = LL_GPIO_MODE_ANALOG;
  GPIO_InitStruct.Pull = LL_GPIO_PULL_NO;
  LL_GPIO_Init(GPIOD, &GPIO_InitStruct);

  /**/
  GPIO_InitStruct.Pin = LL_GPIO_PIN_11;
  GPIO_InitStruct.Mode = LL_GPIO_MODE_ANALOG;
  GPIO_InitStruct.Pull = LL_GPIO_PULL_NO;
  LL_GPIO_Init(GPIOD, &GPIO_InitStruct);

  /**/
  GPIO_InitStruct.Pin = LL_GPIO_PIN_12;
  GPIO_InitStruct.Mode = LL_GPIO_MODE_ANALOG;
  GPIO_InitStruct.Pull = LL_GPIO_PULL_NO;
  LL_GPIO_Init(GPIOD, &GPIO_InitStruct);

  /**/
  GPIO_InitStruct.Pin = LL_GPIO_PIN_13;
  GPIO_InitStruct.Mode = LL_GPIO_MODE_ANALOG;
  GPIO_InitStruct.Pull = LL_GPIO_PULL_NO;
  LL_GPIO_Init(GPIOD, &GPIO_InitStruct);

  /**/
  GPIO_InitStruct.Pin = LL_GPIO_PIN_14;
  GPIO_InitStruct.Mode = LL_GPIO_MODE_ANALOG;
  GPIO_InitStruct.Pull = LL_GPIO_PULL_NO;
  LL_GPIO_Init(GPIOD, &GPIO_InitStruct);

  /**/
  GPIO_InitStruct.Pin = LL_GPIO_PIN_15;
  GPIO_InitStruct.Mode = LL_GPIO_MODE_ANALOG;
  GPIO_InitStruct.Pull = LL_GPIO_PULL_NO;
  LL_GPIO_Init(GPIOD, &GPIO_InitStruct);

  /**/
  GPIO_InitStruct.Pin = LL_GPIO_PIN_6;
  GPIO_InitStruct.Mode = LL_GPIO_MODE_ANALOG;
  GPIO_InitStruct.Pull = LL_GPIO_PULL_NO;
  LL_GPIO_Init(GPIOC, &GPIO_InitStruct);

  /**/
  GPIO_InitStruct.Pin = LL_GPIO_PIN_7;
  GPIO_InitStruct.Mode = LL_GPIO_MODE_ANALOG;
  GPIO_InitStruct.Pull = LL_GPIO_PULL_NO;
  LL_GPIO_Init(GPIOC, &GPIO_InitStruct);

  /**/
  GPIO_InitStruct.Pin = LL_GPIO_PIN_8;
  GPIO_InitStruct.Mode = LL_GPIO_MODE_ANALOG;
  GPIO_InitStruct.Pull = LL_GPIO_PULL_NO;
  LL_GPIO_Init(GPIOA, &GPIO_InitStruct);

  /**/
  GPIO_InitStruct.Pin = LL_GPIO_PIN_9;
  GPIO_InitStruct.Mode = LL_GPIO_MODE_ANALOG;
  GPIO_InitStruct.Pull = LL_GPIO_PULL_NO;
  LL_GPIO_Init(GPIOA, &GPIO_InitStruct);

  /**/
  GPIO_InitStruct.Pin = LL_GPIO_PIN_10;
  GPIO_InitStruct.Mode = LL_GPIO_MODE_ANALOG;
  GPIO_InitStruct.Pull = LL_GPIO_PULL_NO;
  LL_GPIO_Init(GPIOA, &GPIO_InitStruct);

  /**/
  GPIO_InitStruct.Pin = LL_GPIO_PIN_11;
  GPIO_InitStruct.Mode = LL_GPIO_MODE_ANALOG;
  GPIO_InitStruct.Pull = LL_GPIO_PULL_NO;
  LL_GPIO_Init(GPIOA, &GPIO_InitStruct);

  /**/
  GPIO_InitStruct.Pin = LL_GPIO_PIN_12;
  GPIO_InitStruct.Mode = LL_GPIO_MODE_ANALOG;
  GPIO_InitStruct.Pull = LL_GPIO_PULL_NO;
  LL_GPIO_Init(GPIOA, &GPIO_InitStruct);

  /**/
  GPIO_InitStruct.Pin = LL_GPIO_PIN_15;
  GPIO_InitStruct.Mode = LL_GPIO_MODE_ANALOG;
  GPIO_InitStruct.Pull = LL_GPIO_PULL_NO;
  LL_GPIO_Init(GPIOA, &GPIO_InitStruct);

  /**/
  GPIO_InitStruct.Pin = LL_GPIO_PIN_10;
  GPIO_InitStruct.Mode = LL_GPIO_MODE_ANALOG;
  GPIO_InitStruct.Pull = LL_GPIO_PULL_NO;
  LL_GPIO_Init(GPIOC, &GPIO_InitStruct);

  /**/
  GPIO_InitStruct.Pin = LL_GPIO_PIN_11;
  GPIO_InitStruct.Mode = LL_GPIO_MODE_ANALOG;
  GPIO_InitStruct.Pull = LL_GPIO_PULL_NO;
  LL_GPIO_Init(GPIOC, &GPIO_InitStruct);

  /**/
  GPIO_InitStruct.Pin = LL_GPIO_PIN_12;
  GPIO_InitStruct.Mode = LL_GPIO_MODE_ANALOG;
  GPIO_InitStruct.Pull = LL_GPIO_PULL_NO;
  LL_GPIO_Init(GPIOC, &GPIO_InitStruct);

  /**/
  GPIO_InitStruct.Pin = LL_GPIO_PIN_0;
  GPIO_InitStruct.Mode = LL_GPIO_MODE_ANALOG;
  GPIO_InitStruct.Pull = LL_GPIO_PULL_NO;
  LL_GPIO_Init(GPIOD, &GPIO_InitStruct);

  /**/
  GPIO_InitStruct.Pin = LL_GPIO_PIN_1;
  GPIO_InitStruct.Mode = LL_GPIO_MODE_ANALOG;
  GPIO_InitStruct.Pull = LL_GPIO_PULL_NO;
  LL_GPIO_Init(GPIOD, &GPIO_InitStruct);

  /**/
  GPIO_InitStruct.Pin = LL_GPIO_PIN_2;
  GPIO_InitStruct.Mode = LL_GPIO_MODE_ANALOG;
  GPIO_InitStruct.Pull = LL_GPIO_PULL_NO;
  LL_GPIO_Init(GPIOD, &GPIO_InitStruct);

  /**/
  GPIO_InitStruct.Pin = LL_GPIO_PIN_3;
  GPIO_InitStruct.Mode = LL_GPIO_MODE_ANALOG;
  GPIO_InitStruct.Pull = LL_GPIO_PULL_NO;
  LL_GPIO_Init(GPIOD, &GPIO_InitStruct);

  /**/
  GPIO_InitStruct.Pin = LL_GPIO_PIN_4;
  GPIO_InitStruct.Mode = LL_GPIO_MODE_ANALOG;
  GPIO_InitStruct.Pull = LL_GPIO_PULL_NO;
  LL_GPIO_Init(GPIOD, &GPIO_InitStruct);

  /**/
  GPIO_InitStruct.Pin = LL_GPIO_PIN_5;
  GPIO_InitStruct.Mode = LL_GPIO_MODE_ANALOG;
  GPIO_InitStruct.Pull = LL_GPIO_PULL_NO;
  LL_GPIO_Init(GPIOD, &GPIO_InitStruct);

  /**/
  GPIO_InitStruct.Pin = LL_GPIO_PIN_6;
  GPIO_InitStruct.Mode = LL_GPIO_MODE_ANALOG;
  GPIO_InitStruct.Pull = LL_GPIO_PULL_NO;
  LL_GPIO_Init(GPIOD, &GPIO_InitStruct);

  /**/
  GPIO_InitStruct.Pin = LL_GPIO_PIN_7;
  GPIO_InitStruct.Mode = LL_GPIO_MODE_ANALOG;
  GPIO_InitStruct.Pull = LL_GPIO_PULL_NO;
  LL_GPIO_Init(GPIOD, &GPIO_InitStruct);

  /**/
  GPIO_InitStruct.Pin = LL_GPIO_PIN_3;
  GPIO_InitStruct.Mode = LL_GPIO_MODE_ANALOG;
  GPIO_InitStruct.Pull = LL_GPIO_PULL_NO;
  LL_GPIO_Init(GPIOB, &GPIO_InitStruct);

  /**/
  GPIO_InitStruct.Pin = LL_GPIO_PIN_4;
  GPIO_InitStruct.Mode = LL_GPIO_MODE_ANALOG;
  GPIO_InitStruct.Pull = LL_GPIO_PULL_NO;
  LL_GPIO_Init(GPIOB, &GPIO_InitStruct);

  /**/
  GPIO_InitStruct.Pin = LL_GPIO_PIN_5;
  GPIO_InitStruct.Mode = LL_GPIO_MODE_ANALOG;
  GPIO_InitStruct.Pull = LL_GPIO_PULL_NO;
  LL_GPIO_Init(GPIOB, &GPIO_InitStruct);

  /**/
  GPIO_InitStruct.Pin = LL_GPIO_PIN_6;
  GPIO_InitStruct.Mode = LL_GPIO_MODE_OUTPUT;
  GPIO_InitStruct.Speed = LL_GPIO_SPEED_FREQ_LOW;
  GPIO_InitStruct.OutputType = LL_GPIO_OUTPUT_PUSHPULL;
  GPIO_InitStruct.Pull = LL_GPIO_PULL_NO;
  LL_GPIO_Init(GPIOB, &GPIO_InitStruct);

  /**/
  GPIO_InitStruct.Pin = LL_GPIO_PIN_7;
  GPIO_InitStruct.Mode = LL_GPIO_MODE_OUTPUT;
  GPIO_InitStruct.Speed = LL_GPIO_SPEED_FREQ_LOW;
  GPIO_InitStruct.OutputType = LL_GPIO_OUTPUT_PUSHPULL;
  GPIO_InitStruct.Pull = LL_GPIO_PULL_NO;
  LL_GPIO_Init(GPIOB, &GPIO_InitStruct);

  /**/
  GPIO_InitStruct.Pin = LL_GPIO_PIN_8;
  GPIO_InitStruct.Mode = LL_GPIO_MODE_ANALOG;
  GPIO_InitStruct.Pull = LL_GPIO_PULL_NO;
  LL_GPIO_Init(GPIOB, &GPIO_InitStruct);

  /**/
  GPIO_InitStruct.Pin = LL_GPIO_PIN_9;
  GPIO_InitStruct.Mode = LL_GPIO_MODE_ANALOG;
  GPIO_InitStruct.Pull = LL_GPIO_PULL_NO;
  LL_GPIO_Init(GPIOB, &GPIO_InitStruct);

  /**/
  GPIO_InitStruct.Pin = LL_GPIO_PIN_0;
  GPIO_InitStruct.Mode = LL_GPIO_MODE_ANALOG;
  GPIO_InitStruct.Pull = LL_GPIO_PULL_NO;
  LL_GPIO_Init(GPIOE, &GPIO_InitStruct);

  /**/
  GPIO_InitStruct.Pin = LL_GPIO_PIN_1;
  GPIO_InitStruct.Mode = LL_GPIO_MODE_ANALOG;
  GPIO_InitStruct.Pull = LL_GPIO_PULL_NO;
  LL_GPIO_Init(GPIOE, &GPIO_InitStruct);

}

void Error_Handler(void)
{
  __disable_irq();
  while (1)
  {
  }
}
